VERSION "HIPBNYYYYYYYYYYYYYYYYYYYYYYYYYYYYYYYYYYYYY/4/%%%/4/'%**4YYY///"

NS_ :

BS_:

BU_: INV BMS VCU DASH DATALOGGER PDB EMeter REPRO TELEM

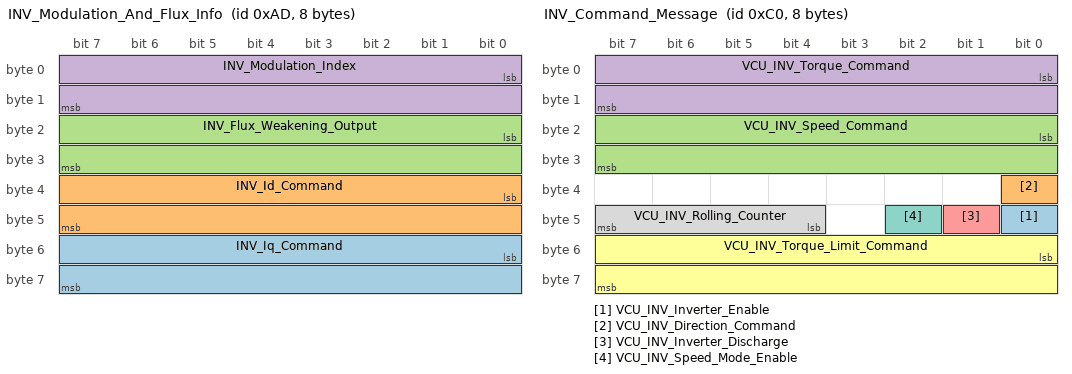
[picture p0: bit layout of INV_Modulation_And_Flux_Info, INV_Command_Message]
BO_ 173 INV_Modulation_And_Flux_Info: 8 INV
 SG_ INV_Iq_Command : 48|16@1- (0.1,0) [-3276.8|3276.7] "current:A" Vector__XXX
 SG_ INV_Id_Command : 32|16@1- (0.1,0) [-3276.8|3276.7] "current:A" Vector__XXX
 SG_ INV_Flux_Weakening_Output : 16|16@1- (0.1,0) [-3276.8|3276.7] "current:A" Vector__XXX
 SG_ INV_Modulation_Index : 0|16@1- (0.0001,0) [-3.2768|3.2767] "" Vector__XXX

BO_ 172 INV_Torque_And_Timer_Info: 8 INV
 SG_ INV_Power_On_Timer : 32|32@1+ (0.003,0) [0|12884800] "time:second" Vector__XXX
 SG_ INV_Torque_Feedback : 16|16@1- (0.1,0) [-3276.8|3276.7] "torque:N.m" Vector__XXX
 SG_ INV_Commanded_Torque : 0|16@1- (0.1,0) [-3276.8|3276.7] "torque:N.m" Vector__XXX

BO_ 194 INV_Parameter_Response: 8 INV
 SG_ INV_Parameter_Response_Write_OK : 16|1@1+ (1,0) [0|1] "" Vector__XXX
 SG_ INV_Parameter_Response_Data : 32|16@1- (1,0) [-32768|32767] "" Vector__XXX
 SG_ INV_Parameter_Response_Addr : 0|16@1+ (1,0) [0|65535] "" Vector__XXX

BO_ 193 INV_Parameter_Command: 8 VCU
 SG_ VCU_INV_Parameter_Data : 32|16@1- (1,0) [-32768|32767] "" Vector__XXX
 SG_ VCU_INV_Parameter_RW_Command : 16|1@1+ (1,0) [0|1] "" Vector__XXX
 SG_ VCU_INV_Parameter_Address : 0|16@1+ (1,0) [0|65535] "" Vector__XXX

BO_ 192 INV_Command_Message: 8 VCU
 SG_ VCU_INV_Inverter_Enable : 40|1@1+ (1,0) [0|1] "" Vector__XXX
 SG_ VCU_INV_Direction_Command : 32|1@1+ (1,0) [0|1] "" Vector__XXX
 SG_ VCU_INV_Speed_Command : 16|16@1- (1,0) [-32768|32767] "angular_speed:rpm" Vector__XXX
 SG_ VCU_INV_Torque_Command : 0|16@1- (0.1,0) [-3276.8|3276.7] "torque:N.m" Vector__XXX
 SG_ VCU_INV_Inverter_Discharge : 41|1@1+ (1,0) [0|1] "" Vector__XXX
 SG_ VCU_INV_Torque_Limit_Command : 48|16@1- (0.1,0) [-3276.8|3276.7] "torque:N.m" Vector__XXX
 SG_ VCU_INV_Speed_Mode_Enable : 42|1@1+ (1,0) [0|1] "" Vector__XXX
 SG_ VCU_INV_Rolling_Counter : 44|4@1+ (1,0) [0|15] "" Vector__XXX

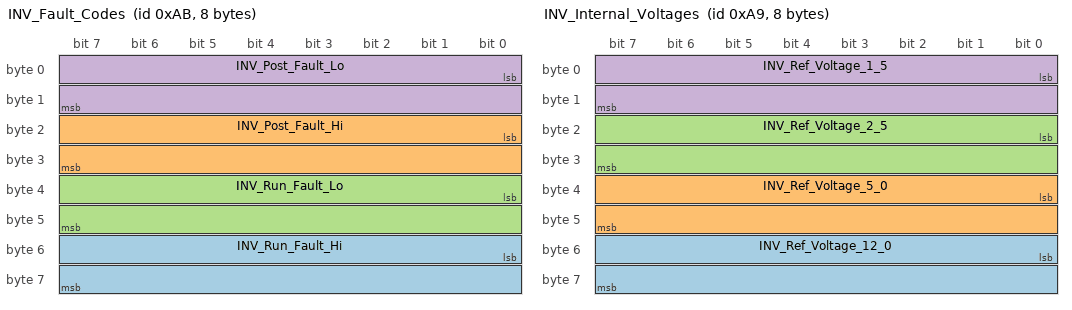
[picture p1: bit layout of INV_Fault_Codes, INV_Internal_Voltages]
BO_ 171 INV_Fault_Codes: 8 INV
 SG_ INV_Run_Fault_Hi : 48|16@1+ (1,0) [0|65535] "" Vector__XXX
 SG_ INV_Post_Fault_Hi : 16|16@1+ (1,0) [0|65535] "" Vector__XXX
 SG_ INV_Run_Fault_Lo : 32|16@1+ (1,0) [0|65535] "" Vector__XXX
 SG_ INV_Post_Fault_Lo : 0|16@1+ (1,0) [0|65535] "" Vector__XXX

BO_ 170 INV_Internal_States: 8 INV
 SG_ INV_Direction_Command : 56|1@1+ (1,0) [0|1] "" Vector__XXX
 SG_ INV_Inverter_Enable_State : 48|1@1+ (1,0) [0|1] "" Vector__XXX
 SG_ INV_Relay_3_Status : 26|1@1+ (1,0) [0|1] "" Vector__XXX
 SG_ INV_Relay_4_Status : 27|1@1+ (1,0) [0|1] "" Vector__XXX
 SG_ INV_Relay_2_Status : 25|1@1+ (1,0) [0|1] "" Vector__XXX
 SG_ INV_Inverter_Run_Mode : 32|1@1+ (1,0) [0|1] "" Vector__XXX
 SG_ INV_Inverter_Command_Mode : 40|1@1+ (1,0) [0|1] "" Vector__XXX
 SG_ INV_Relay_1_Status : 24|1@1+ (1,0) [0|1] "" Vector__XXX
 SG_ INV_Inverter_State : 16|8@1+ (1,0) [0|255] "" Vector__XXX
 SG_ INV_VSM_State : 0|8@1+ (1,0) [0|15] "" Vector__XXX
 SG_ INV_Inverter_Enable_Lockout : 55|1@1+ (1,0) [0|1] "" Vector__XXX
 SG_ INV_Inverter_Discharge_State : 37|3@1+ (1,0) [0|7] "" Vector__XXX
 SG_ INV_Relay_5_Status : 28|1@1+ (1,0) [0|1] "" Vector__XXX
 SG_ INV_Relay_6_Status : 29|1@1+ (1,0) [0|1] "" Vector__XXX
 SG_ INV_BMS_Active : 57|1@1+ (1,0) [0|1] "" Vector__XXX
 SG_ INV_BMS_Torque_Limiting : 58|1@1+ (1,0) [0|1] "" Vector__XXX
 SG_ INV_PWM_Frequency : 8|8@1+ (1,0) [0|255] "" Vector__XXX
 SG_ INV_Limit_Max_Speed : 59|1@1+ (1,0) [0|1] "" Vector__XXX
 SG_ INV_Limit_Hot_Spot : 60|1@1+ (1,0) [0|1] "" Vector__XXX
 SG_ INV_Low_Speed_Limiting : 61|1@1+ (1,0) [0|1] "" Vector__XXX
 SG_ INV_Rolling_Counter : 44|4@1+ (1,0) [0|15] "" Vector__XXX
 SG_ INV_Limit_Coolant_Derating : 62|1@1+ (1,0) [0|1] "" Vector__XXX
 SG_ INV_Self_Sensing_Assist_Enable : 33|1@1+ (1,0) [0|1] "" Vector__XXX
 SG_ INV_Limit_Stall_Burst_Model : 63|1@1+ (1,0) [0|1] "" Vector__XXX
 SG_ INV_Burst_Model_Mode : 49|1@1+ (1,0) [0|1] "" Vector__XXX
 SG_ INV_Key_Switch_Start_Status : 54|1@1+ (1,0) [0|1] "" Vector__XXX

BO_ 169 INV_Internal_Voltages: 8 INV
 SG_ INV_Ref_Voltage_12_0 : 48|16@1- (0.01,0) [-327.68|327.67] "voltage:V" Vector__XXX
 SG_ INV_Ref_Voltage_5_0 : 32|16@1- (0.01,0) [-327.68|327.67] "voltage:V" Vector__XXX
 SG_ INV_Ref_Voltage_2_5 : 16|16@1- (0.01,0) [-327.68|327.67] "voltage:V" Vector__XXX
 SG_ INV_Ref_Voltage_1_5 : 0|16@1- (0.01,0) [-327.68|327.67] "voltage:V" Vector__XXX

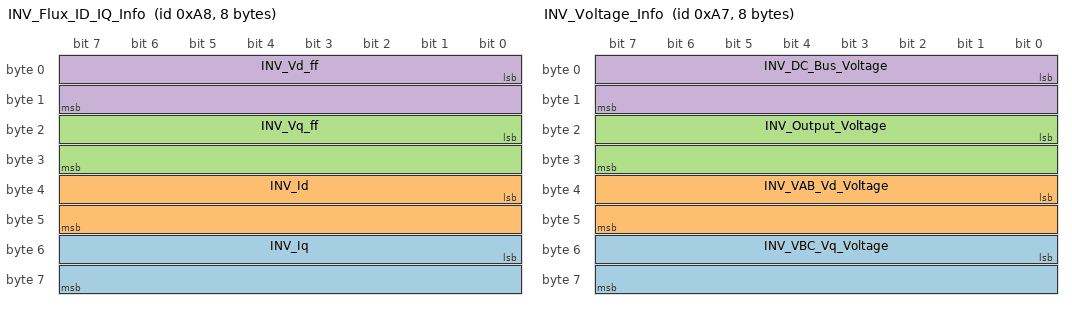
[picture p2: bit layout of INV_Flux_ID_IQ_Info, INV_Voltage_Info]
BO_ 168 INV_Flux_ID_IQ_Info: 8 INV
 SG_ INV_Iq : 48|16@1- (0.1,0) [-3276.8|3276.7] "current:A" Vector__XXX
 SG_ INV_Id : 32|16@1- (0.1,0) [-3276.8|3276.7] "current:A" Vector__XXX
 SG_ INV_Vq_ff : 16|16@1- (0.1,0) [-3276.7|3276.7] "voltage:V" Vector__XXX
 SG_ INV_Vd_ff : 0|16@1- (0.1,0) [-3276.7|3276.7] "voltage:V" Vector__XXX

BO_ 167 INV_Voltage_Info: 8 INV
 SG_ INV_VBC_Vq_Voltage : 48|16@1- (0.1,0) [-3276.8|3276.7] "voltage:V" Vector__XXX
 SG_ INV_VAB_Vd_Voltage : 32|16@1- (0.1,0) [-3276.8|3276.7] "voltage:V" Vector__XXX
 SG_ INV_Output_Voltage : 16|16@1- (0.1,0) [-3276.8|3276.7] "voltage:V" Vector__XXX
 SG_ INV_DC_Bus_Voltage : 0|16@1- (0.1,0) [-3276.8|3276.7] "voltage:V" Vector__XXX

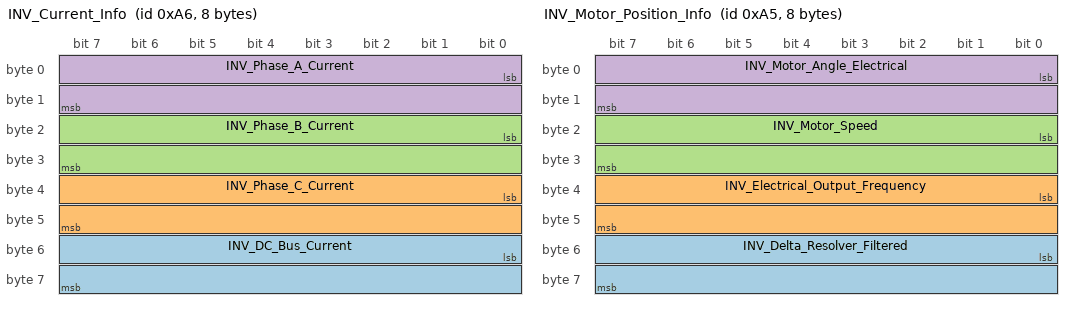
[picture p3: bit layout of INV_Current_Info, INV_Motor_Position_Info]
BO_ 166 INV_Current_Info: 8 INV
 SG_ INV_DC_Bus_Current : 48|16@1- (0.1,0) [-3276.8|3276.7] "current:A" Vector__XXX
 SG_ INV_Phase_C_Current : 32|16@1- (0.1,0) [-3276.8|3276.7] "current:A" Vector__XXX
 SG_ INV_Phase_B_Current : 16|16@1- (0.1,0) [-3276.8|3276.7] "current:A" Vector__XXX
 SG_ INV_Phase_A_Current : 0|16@1- (0.1,0) [-3276.8|3276.7] "current:A" Vector__XXX

BO_ 165 INV_Motor_Position_Info: 8 INV
 SG_ INV_Delta_Resolver_Filtered : 48|16@1- (0.1,0) [-3276.8|3276.7] "angle:deg" Vector__XXX
 SG_ INV_Electrical_Output_Frequency : 32|16@1- (0.1,0) [-3276.8|3276.7] "frequency:Hz" Vector__XXX
 SG_ INV_Motor_Speed : 16|16@1- (1,0) [-32768|32767] "angular_speed:rpm" Vector__XXX
 SG_ INV_Motor_Angle_Electrical : 0|16@1+ (0.1,0) [0|6553.5] "angle:deg" Vector__XXX

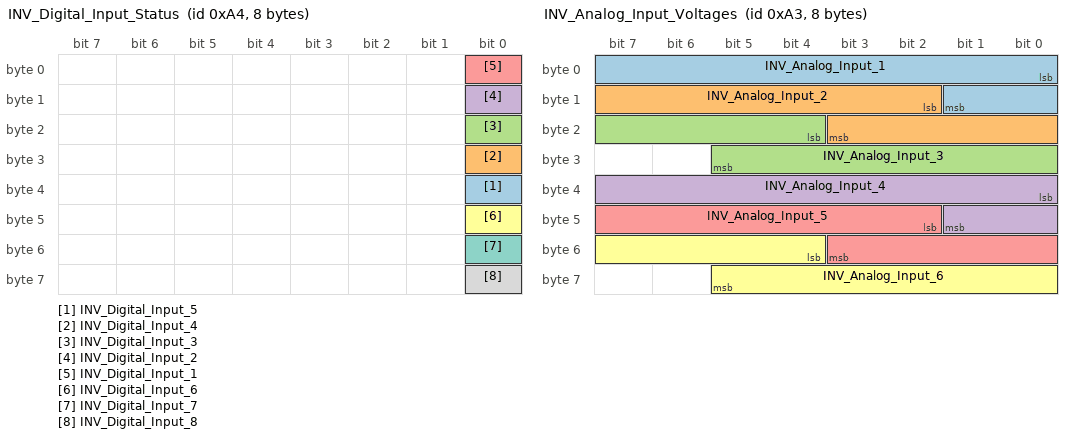
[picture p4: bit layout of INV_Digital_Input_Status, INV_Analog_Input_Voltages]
BO_ 164 INV_Digital_Input_Status: 8 INV
 SG_ INV_Digital_Input_5 : 32|1@1+ (1,0) [0|1] "" Vector__XXX
 SG_ INV_Digital_Input_4 : 24|1@1+ (1,0) [0|1] "" Vector__XXX
 SG_ INV_Digital_Input_3 : 16|1@1+ (1,0) [0|1] "" Vector__XXX
 SG_ INV_Digital_Input_2 : 8|1@1+ (1,0) [0|1] "" Vector__XXX
 SG_ INV_Digital_Input_1 : 0|1@1+ (1,0) [0|1] "" Vector__XXX
 SG_ INV_Digital_Input_6 : 40|1@1+ (1,0) [0|1] "" Vector__XXX
 SG_ INV_Digital_Input_7 : 48|1@1+ (1,0) [0|1] "" Vector__XXX
 SG_ INV_Digital_Input_8 : 56|1@1+ (1,0) [0|1] "" Vector__XXX

BO_ 163 INV_Analog_Input_Voltages: 8 INV
 SG_ INV_Analog_Input_1 : 0|10@1+ (0.01,0) [0|10.23] "voltage:V" Vector__XXX
 SG_ INV_Analog_Input_2 : 10|10@1+ (0.01,0) [0|10.23] "voltage:V" Vector__XXX
 SG_ INV_Analog_Input_3 : 20|10@1+ (0.01,0) [0|10.23] "voltage:V" Vector__XXX
 SG_ INV_Analog_Input_4 : 32|10@1+ (0.01,0) [0|10.23] "voltage:V" Vector__XXX
 SG_ INV_Analog_Input_5 : 42|10@1+ (0.01,0) [0|10.23] "voltage:V" Vector__XXX
 SG_ INV_Analog_Input_6 : 52|10@1+ (0.01,0) [0|10.23] "voltage:V" Vector__XXX

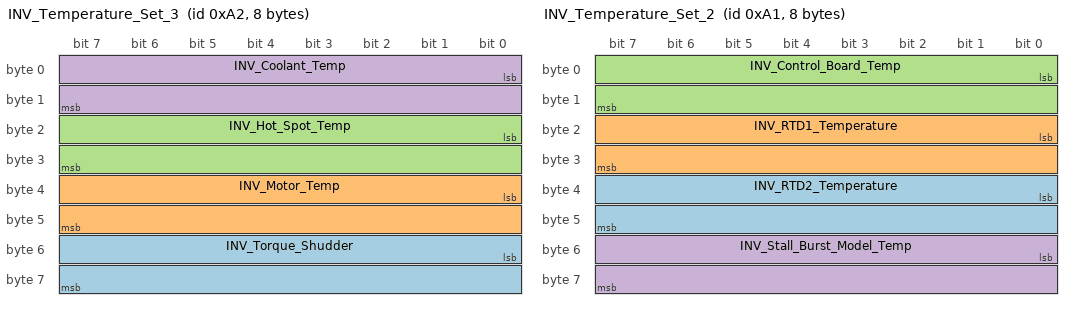
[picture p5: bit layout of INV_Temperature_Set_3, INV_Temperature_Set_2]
BO_ 162 INV_Temperature_Set_3: 8 INV
 SG_ INV_Torque_Shudder : 48|16@1- (0.1,0) [-3276.8|3276.7] "torque:N.m" Vector__XXX
 SG_ INV_Motor_Temp : 32|16@1- (0.1,0) [-3276.8|3276.7] "temperature:C" Vector__XXX
 SG_ INV_Hot_Spot_Temp : 16|16@1- (0.1,0) [-3276.8|3276.7] "temperature:C" Vector__XXX
 SG_ INV_Coolant_Temp : 0|16@1- (0.1,0) [-3276.8|3276.7] "temperature:C" Vector__XXX

BO_ 161 INV_Temperature_Set_2: 8 INV
 SG_ INV_RTD2_Temperature : 32|16@1- (0.1,0) [-3276.8|3276.7] "temperature:C" Vector__XXX
 SG_ INV_RTD1_Temperature : 16|16@1- (0.1,0) [-3276.8|3276.7] "temperature:C" Vector__XXX
 SG_ INV_Control_Board_Temp : 0|16@1- (0.1,0) [-3276.8|3276.7] "temperature:C" Vector__XXX
 SG_ INV_Stall_Burst_Model_Temp : 48|16@1- (0.1,0) [-3276.8|3276.7] "temperature:C" Vector__XXX

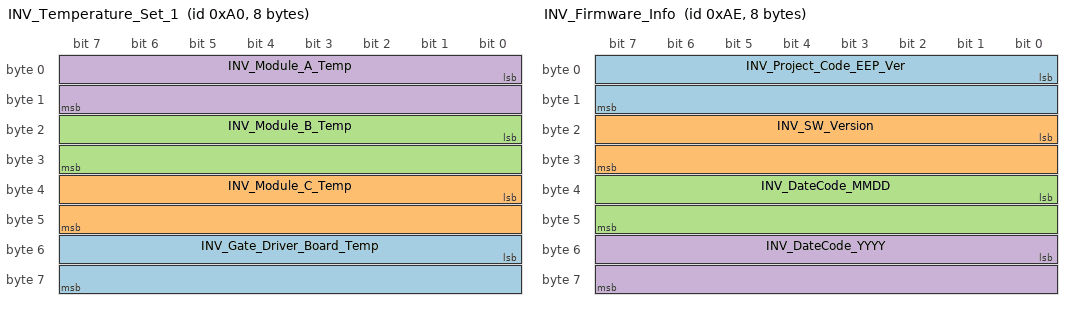
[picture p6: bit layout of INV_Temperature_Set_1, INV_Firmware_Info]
BO_ 160 INV_Temperature_Set_1: 8 INV
 SG_ INV_Gate_Driver_Board_Temp : 48|16@1- (0.1,0) [-3276.8|3276.7] "temperature:C" Vector__XXX
 SG_ INV_Module_C_Temp : 32|16@1- (0.1,0) [-3276.8|3276.7] "temperature:C" Vector__XXX
 SG_ INV_Module_B_Temp : 16|16@1- (0.1,0) [-3276.8|3276.7] "temperature:C" Vector__XXX
 SG_ INV_Module_A_Temp : 0|16@1- (0.1,0) [-3276.8|3276.7] "temperature:C" Vector__XXX

BO_ 174 INV_Firmware_Info: 8 INV
 SG_ INV_Project_Code_EEP_Ver : 0|16@1+ (1,0) [0|65535] "" Vector__XXX
 SG_ INV_SW_Version : 16|16@1+ (1,0) [0|65535] "" Vector__XXX
 SG_ INV_DateCode_MMDD : 32|16@1+ (1,0) [0|65535] "" Vector__XXX
 SG_ INV_DateCode_YYYY : 48|16@1+ (1,0) [0|65535] "" Vector__XXX

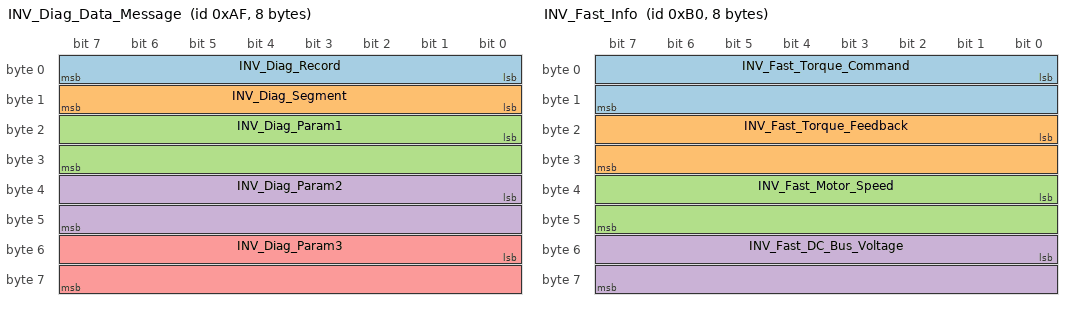
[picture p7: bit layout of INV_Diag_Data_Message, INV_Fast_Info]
BO_ 175 INV_Diag_Data_Message: 8 INV
 SG_ INV_Diag_Record : 0|8@1+ (1,0) [0|160] "" Vector__XXX
 SG_ INV_Diag_Segment M : 8|8@1+ (1,0) [0|5] "" Vector__XXX
 SG_ INV_Diag_Param1 : 16|16@1+ (1,0) [0|0] "" Vector__XXX
 SG_ INV_Diag_Param2 : 32|16@1+ (1,0) [0|0] "" Vector__XXX
 SG_ INV_Diag_Param3 : 48|16@1+ (1,0) [0|0] "" Vector__XXX

BO_ 176 INV_Fast_Info: 8 INV
 SG_ INV_Fast_Torque_Command : 0|16@1- (0.1,0) [-3276.8|32767.7] "torque:N.m" Vector__XXX
 SG_ INV_Fast_Torque_Feedback : 16|16@1- (0.1,0) [-3276.8|3276.7] "torque:N.m" Vector__XXX
 SG_ INV_Fast_Motor_Speed : 32|16@1- (1,0) [-32768|32767] "angular_speed:rpm" Vector__XXX
 SG_ INV_Fast_DC_Bus_Voltage : 48|16@1- (0.1,0) [-3276.8|3276.7] "voltage:V" Vector__XXX

BO_ 177 INV_Torque_Capability: 8 INV
 SG_ INV_Torque_Capability : 0|16@1+ (0.1,0) [0|6553.6] "torque:N.m" Vector__XXX

BO_ 244 BMS_ChargerCtrl: 8 BMS
 SG_ BMS_Max_Charging_Voltage : 7|16@0+ (0.1,0) [0|6553.5] "voltage:V" Vector__XXX
 SG_ BMS_Max_Charging_Current : 23|16@0+ (0.1,0) [0|6553.5] "current:A" Vector__XXX
 SG_ BMS_Charger_Enable : 32|1@1+ (1,0) [0|1] "" Vector__XXX

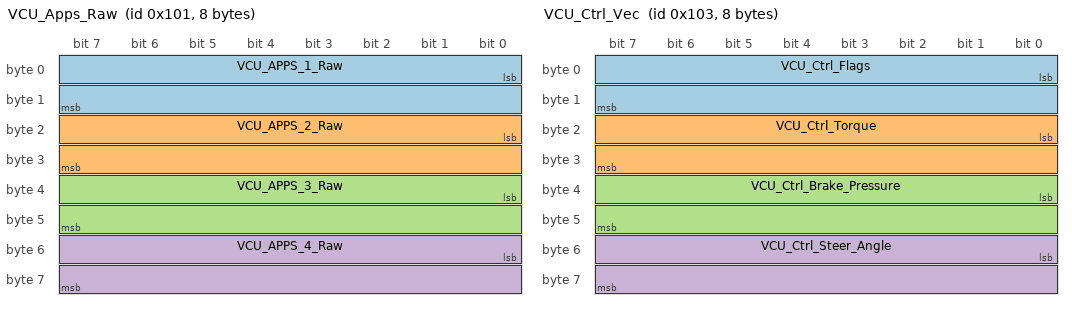
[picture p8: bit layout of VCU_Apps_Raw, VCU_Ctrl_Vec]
BO_ 257 VCU_Apps_Raw: 8 VCU
 SG_ VCU_APPS_1_Raw : 0|16@1+ (1,0) [0|4096] "" Vector__XXX
 SG_ VCU_APPS_2_Raw : 16|16@1+ (1,0) [0|4096] "" Vector__XXX
 SG_ VCU_APPS_3_Raw : 32|16@1+ (1,0) [0|4096] "" Vector__XXX
 SG_ VCU_APPS_4_Raw : 48|16@1+ (1,0) [0|4096] "" Vector__XXX

BO_ 258 VCU_BPS_Raw: 4 VCU
 SG_ VCU_FBPS_Raw : 0|16@1+ (1,0) [0|0] "" Vector__XXX
 SG_ VCU_RBPS_Raw : 16|16@1+ (1,0) [0|0] "" Vector__XXX

BO_ 259 VCU_Ctrl_Vec: 8 VCU
 SG_ VCU_Ctrl_Flags : 0|16@1- (1,0) [0|0] "" Vector__XXX
 SG_ VCU_Ctrl_Torque : 16|16@1- (0.1,0) [-220|220] "torque:N.m" Vector__XXX
 SG_ VCU_Ctrl_Brake_Pressure : 32|16@1+ (0.1,0) [0|300] "pressure:Bar" Vector__XXX
 SG_ VCU_Ctrl_Steer_Angle : 48|16@1+ (1,0) [0|0] "" Vector__XXX

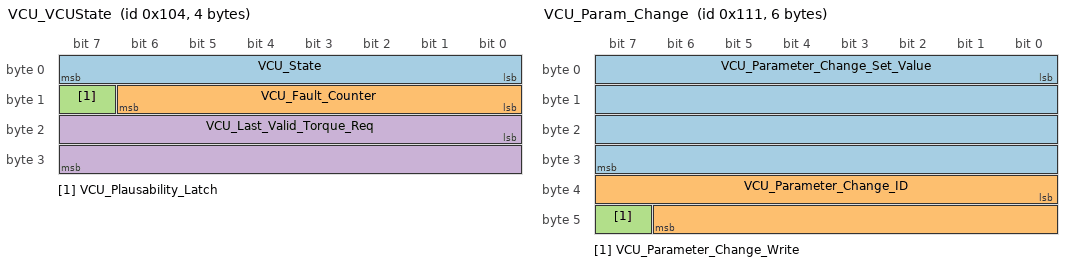
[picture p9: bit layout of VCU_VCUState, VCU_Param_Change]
BO_ 260 VCU_VCUState: 4 VCU
 SG_ VCU_State : 0|8@1+ (1,0) [0|3] "" Vector__XXX
 SG_ VCU_Fault_Counter : 8|7@1+ (1,0) [0|100] "" Vector__XXX
 SG_ VCU_Plausability_Latch : 15|1@1+ (1,0) [0|1] "" Vector__XXX
 SG_ VCU_Last_Valid_Torque_Req : 16|16@1+ (1,0) [0|0] "" Vector__XXX

BO_ 272 VCU_Param_Reveal: 6 VCU
 SG_ VCU_Parameter_Reveal_Set_Value : 0|32@1+ (1,0) [0|0] "" Vector__XXX
 SG_ VCU_Parameter_Reveal_ID : 32|16@1+ (1,0) [0|0] "" Vector__XXX

BO_ 273 VCU_Param_Change: 6 REPRO
 SG_ VCU_Parameter_Change_Set_Value : 0|32@1+ (1,0) [0|0] "" Vector__XXX
 SG_ VCU_Parameter_Change_ID : 32|15@1+ (1,0) [0|0] "" Vector__XXX
 SG_ VCU_Parameter_Change_Write : 47|1@1+ (1,0) [0|0] "" Vector__XXX

BO_ 274 VCU_Param_Request: 2 REPRO
 SG_ VCU_Parameter_Request_ID : 0|16@1+ (1,0) [0|0] "" Vector__XXX

BO_ 514 BMS_CM200_Limits: 8 BMS
 SG_ BMS_Discharge_Current_Limit : 0|16@1- (1,0) [0|0] "current:A" Vector__XXX
 SG_ BMS_Charge_Current_Limit : 16|16@1- (1,0) [0|0] "current:A" Vector__XXX

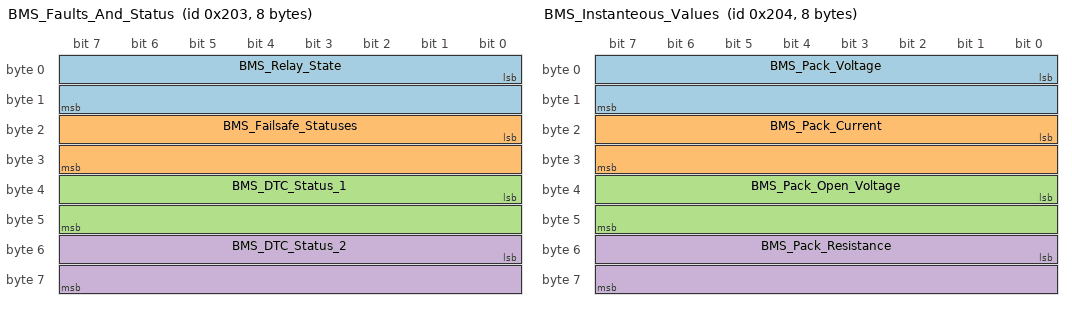
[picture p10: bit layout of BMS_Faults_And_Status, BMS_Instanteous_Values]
BO_ 515 BMS_Faults_And_Status: 8 BMS
 SG_ BMS_Relay_State : 0|16@1+ (1,0) [0|0] "" Vector__XXX
 SG_ BMS_Failsafe_Statuses : 16|16@1+ (1,0) [0|0] "" Vector__XXX
 SG_ BMS_DTC_Status_1 : 32|16@1+ (1,0) [0|0] "" Vector__XXX
 SG_ BMS_DTC_Status_2 : 48|16@1+ (1,0) [0|0] "" Vector__XXX

BO_ 516 BMS_Instanteous_Values: 8 BMS
 SG_ BMS_Pack_Voltage : 0|16@1- (0.1,0) [0|0] "voltage:V" Vector__XXX
 SG_ BMS_Pack_Current : 16|16@1- (0.1,0) [0|0] "current:A" Vector__XXX
 SG_ BMS_Pack_Open_Voltage : 32|16@1- (0.1,0) [0|0] "voltage:V" Vector__XXX
 SG_ BMS_Pack_Resistance : 48|16@1- (0.001,0) [0|0] "resistance:Ohm" Vector__XXX

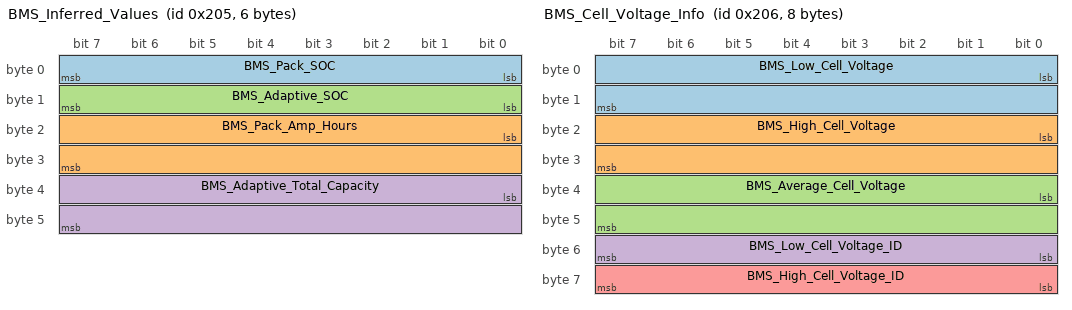
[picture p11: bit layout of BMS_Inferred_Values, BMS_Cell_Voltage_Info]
BO_ 517 BMS_Inferred_Values: 6 BMS
 SG_ BMS_Pack_SOC : 0|8@1+ (0.5,0) [0|0] "percentage:%" Vector__XXX
 SG_ BMS_Pack_Amp_Hours : 16|16@1- (0.1,0) [0|0] "capacity:Ah" Vector__XXX
 SG_ BMS_Adaptive_SOC : 8|8@1+ (0.5,0) [0|0] "percentage:%" Vector__XXX
 SG_ BMS_Adaptive_Total_Capacity : 32|16@1- (0.1,0) [0|0] "capacity:Ah" Vector__XXX

BO_ 518 BMS_Cell_Voltage_Info: 8 BMS
 SG_ BMS_Low_Cell_Voltage : 0|16@1+ (0.001,0) [0|0] "voltage:V" Vector__XXX
 SG_ BMS_High_Cell_Voltage : 16|16@1+ (0.001,0) [0|0] "voltage:V" Vector__XXX
 SG_ BMS_Average_Cell_Voltage : 32|16@1+ (0.001,0) [0|0] "voltage:V" Vector__XXX
 SG_ BMS_Low_Cell_Voltage_ID : 48|8@1+ (1,0) [0|0] "" Vector__XXX
 SG_ BMS_High_Cell_Voltage_ID : 56|8@1+ (1,0) [0|0] "" Vector__XXX

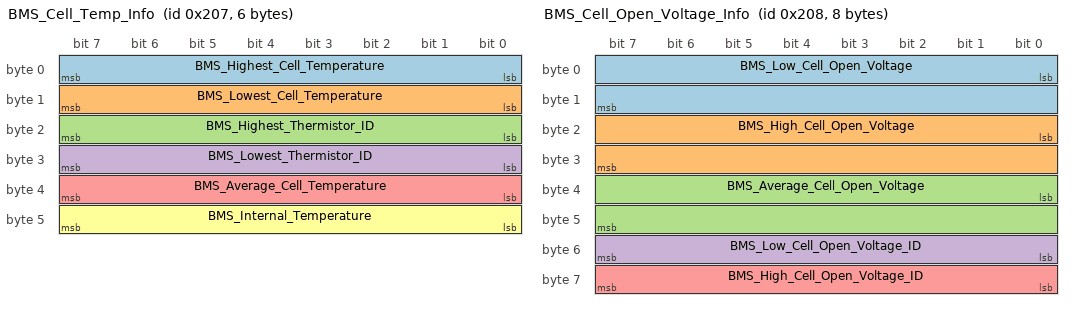
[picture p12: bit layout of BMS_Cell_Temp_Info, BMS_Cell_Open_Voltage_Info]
BO_ 519 BMS_Cell_Temp_Info: 6 BMS
 SG_ BMS_Highest_Cell_Temperature : 0|8@1- (1,0) [0|0] "temperature:C" Vector__XXX
 SG_ BMS_Lowest_Cell_Temperature : 8|8@1- (1,0) [0|0] "temperature:C" Vector__XXX
 SG_ BMS_Highest_Thermistor_ID : 16|8@1+ (1,0) [0|0] "" Vector__XXX
 SG_ BMS_Lowest_Thermistor_ID : 24|8@1+ (1,0) [0|0] "" Vector__XXX
 SG_ BMS_Average_Cell_Temperature : 32|8@1- (1,0) [0|0] "temperature:C" Vector__XXX
 SG_ BMS_Internal_Temperature : 40|8@1- (1,0) [0|0] "temperature:C" Vector__XXX

BO_ 520 BMS_Cell_Open_Voltage_Info: 8 BMS
 SG_ BMS_Low_Cell_Open_Voltage : 0|16@1+ (0.001,0) [0|0] "voltage:V" Vector__XXX
 SG_ BMS_High_Cell_Open_Voltage : 16|16@1+ (0.001,0) [0|0] "voltage:V" Vector__XXX
 SG_ BMS_Average_Cell_Open_Voltage : 32|16@1+ (0.001,0) [0|0] "voltage:V" Vector__XXX
 SG_ BMS_Low_Cell_Open_Voltage_ID : 48|8@1+ (1,0) [0|0] "" Vector__XXX
 SG_ BMS_High_Cell_Open_Voltage_ID : 56|8@1+ (1,0) [0|0] "" Vector__XXX

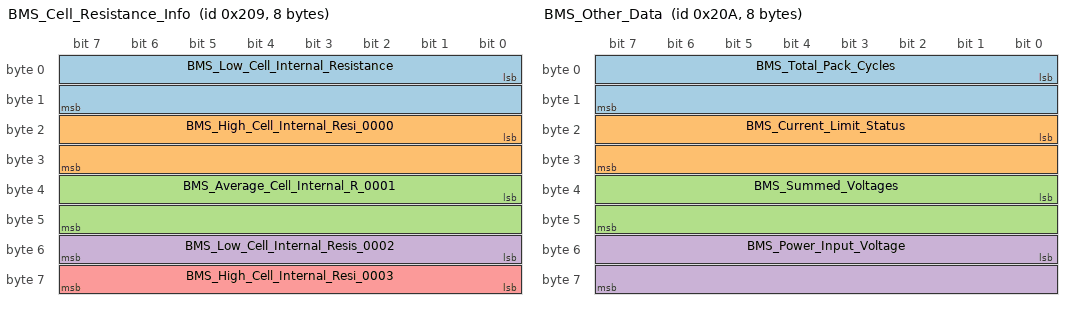
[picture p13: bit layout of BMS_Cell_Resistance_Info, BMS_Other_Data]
BO_ 521 BMS_Cell_Resistance_Info: 8 BMS
 SG_ BMS_Low_Cell_Internal_Resistance : 0|16@1- (0.01,0) [0|0] "resistance:mOhm" Vector__XXX
 SG_ BMS_High_Cell_Internal_Resi_0000 : 16|16@1- (0.01,0) [0|0] "resistance:mOhm" Vector__XXX
 SG_ BMS_Average_Cell_Internal_R_0001 : 32|16@1- (0.01,0) [0|0] "resistance:mOhm" Vector__XXX
 SG_ BMS_Low_Cell_Internal_Resis_0002 : 48|8@1+ (1,0) [0|0] "" Vector__XXX
 SG_ BMS_High_Cell_Internal_Resi_0003 : 56|8@1+ (1,0) [0|0] "" Vector__XXX

BO_ 522 BMS_Other_Data: 8 BMS
 SG_ BMS_Total_Pack_Cycles : 0|16@1+ (1,0) [0|65535] "" Vector__XXX
 SG_ BMS_Current_Limit_Status : 16|16@1+ (1,0) [0|65535] "" Vector__XXX
 SG_ BMS_Summed_Voltages : 32|16@1+ (0.01,0) [0|655.35] "voltage:V" Vector__XXX
 SG_ BMS_Power_Input_Voltage : 48|16@1+ (0.1,0) [0|6553.5] "voltage:V" Vector__XXX

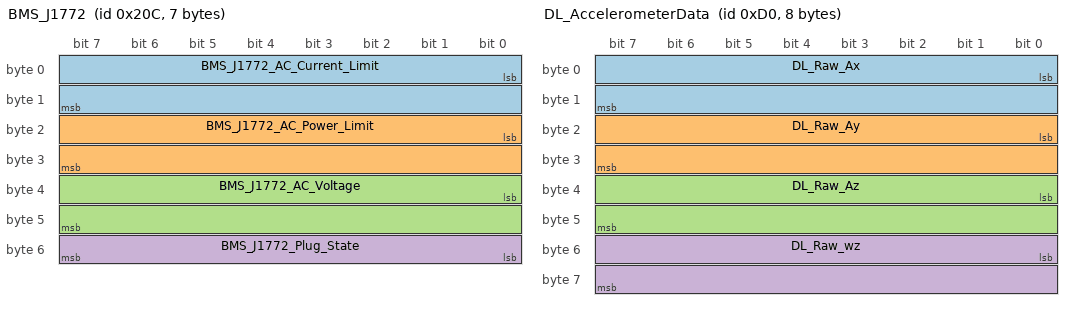
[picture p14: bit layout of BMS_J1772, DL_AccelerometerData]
BO_ 524 BMS_J1772: 7 BMS
 SG_ BMS_J1772_AC_Current_Limit : 0|16@1+ (1,0) [0|0] "" Vector__XXX
 SG_ BMS_J1772_AC_Power_Limit : 16|16@1+ (1,0) [0|0] "" Vector__XXX
 SG_ BMS_J1772_AC_Voltage : 32|16@1+ (1,0) [0|0] "" Vector__XXX
 SG_ BMS_J1772_Plug_State : 48|8@1+ (1,0) [0|0] "" Vector__XXX

BO_ 208 DL_AccelerometerData: 8 DATALOGGER
 SG_ DL_Raw_Ax : 0|16@1- (0.000244140625,0) [-7.9997558594|8] "G" Vector__XXX
 SG_ DL_Raw_Ay : 16|16@1- (0.000244140625,0) [-7.9997558594|8] "G" Vector__XXX
 SG_ DL_Raw_Az : 32|16@1- (0.000244140625,0) [-7.9997558594|8] "G" Vector__XXX
 SG_ DL_Raw_wz : 48|16@1- (0.000244140625,0) [-7.9997558594|8] "angular_speed:rad/s" Vector__XXX

BO_ 209 DL_GPSData: 8 DATALOGGER
 SG_ DL_GPS_Latitude : 0|32@1- (1.1920928955E-07,0) [0|0] "angle:deg" Vector__XXX
 SG_ DL_GPS_Longitude : 32|32@1- (1.1920928955E-07,0) [0|0] "angle:deg" Vector__XXX

BO_ 210 DL_GPSStats: 8 DATALOGGER
 SG_ DL_GPS_DOP : 32|8@1+ (1,0) [0|0] "satellites:N" Vector__XXX
 SG_ DL_GPS_Altitude : 0|32@1- (1,0) [0|0] "height:M" Vector__XXX

BO_ 211 DL_GPSUTC: 8 DATALOGGER
 SG_ DL_GPS_UTC : 0|64@1+ (0.001,0) [0|0] "time:second" Vector__XXX

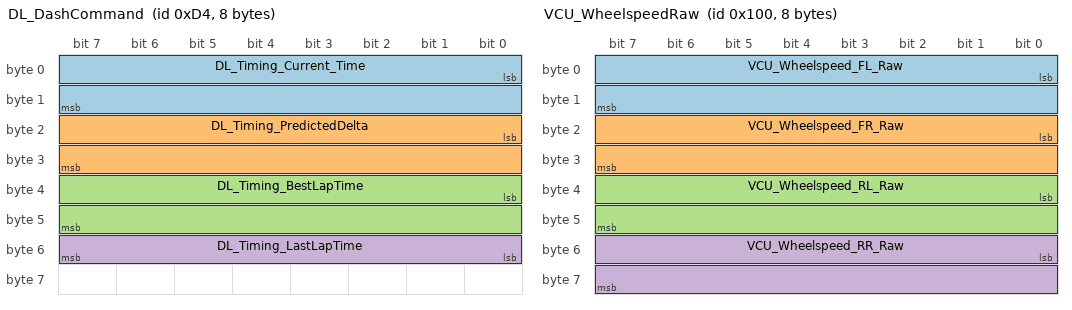
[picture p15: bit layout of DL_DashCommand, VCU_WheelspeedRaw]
BO_ 212 DL_DashCommand: 8 DATALOGGER
 SG_ DL_Timing_Current_Time : 0|16@1+ (0.01,0) [0|0] "time:second"  DASH
 SG_ DL_Timing_PredictedDelta : 16|16@1- (0.01,0) [0|0] "time:second"  DASH
 SG_ DL_Timing_BestLapTime : 32|16@1+ (0.01,0) [0|0] "time:second"  DASH
 SG_ DL_Timing_LastLapTime : 48|8@1+ (0.01,0) [0|0] "time:second"  DASH

BO_ 256 VCU_WheelspeedRaw: 8 VCU
 SG_ VCU_Wheelspeed_FL_Raw : 0|16@1- (0.001,0) [0|0] "angular_speed:rad/s" Vector__XXX
 SG_ VCU_Wheelspeed_FR_Raw : 16|16@1- (0.001,0) [0|0] "angular_speed:rad/s" Vector__XXX
 SG_ VCU_Wheelspeed_RL_Raw : 32|16@1- (0.001,0) [0|0] "angular_speed:rad/s" Vector__XXX
 SG_ VCU_Wheelspeed_RR_Raw : 48|16@1- (0.001,0) [0|0] "angular_speed:rad/s" Vector__XXX

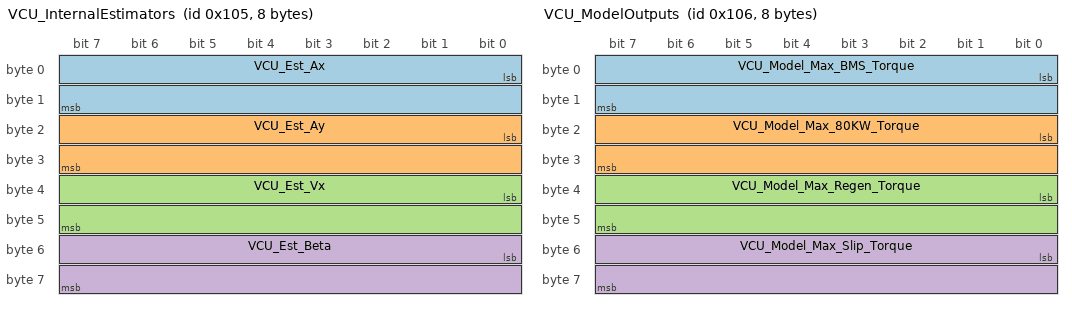
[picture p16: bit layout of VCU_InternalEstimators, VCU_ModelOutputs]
BO_ 261 VCU_InternalEstimators: 8 VCU
 SG_ VCU_Est_Ax : 0|16@1- (0.000244140625,0) [0|0] "acceleration:G" Vector__XXX
 SG_ VCU_Est_Ay : 16|16@1- (0.000244140625,0) [0|0] "acceleration:G" Vector__XXX
 SG_ VCU_Est_Vx : 32|16@1- (0.01,0) [0|0] "speed:m/s" Vector__XXX
 SG_ VCU_Est_Beta : 48|16@1- (0.01,0) [0|0] "angle:deg" Vector__XXX

BO_ 262 VCU_ModelOutputs: 8 VCU
 SG_ VCU_Model_Max_BMS_Torque : 0|16@1- (0.1,0) [0|0] "torque:N.m" Vector__XXX
 SG_ VCU_Model_Max_80KW_Torque : 16|16@1- (0.1,0) [0|0] "torque:N.m" Vector__XXX
 SG_ VCU_Model_Max_Regen_Torque : 32|16@1- (0.1,0) [0|0] "torque:N.m" Vector__XXX
 SG_ VCU_Model_Max_Slip_Torque : 48|16@1- (0.1,0) [0|0] "torque:N.m" Vector__XXX

BO_ 263 VCU_ModelState: 8 VCU
 SG_ VCU_Model_State_Placeholder : 0|64@1+ (1,0) [0|0] "" Vector__XXX

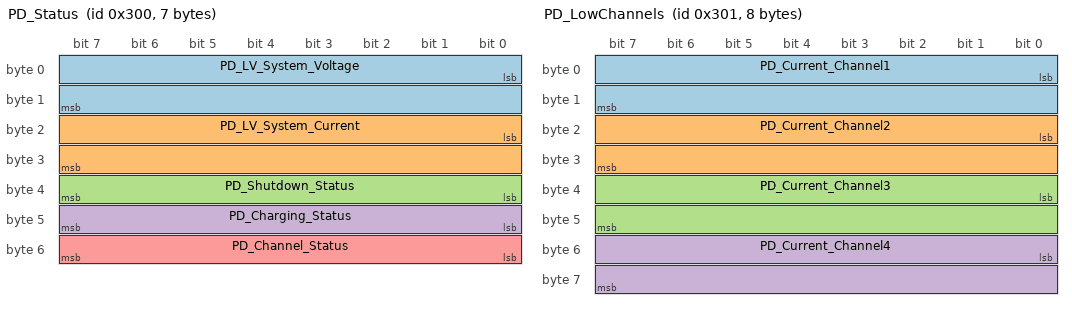
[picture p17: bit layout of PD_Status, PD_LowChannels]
BO_ 768 PD_Status: 7 PDB
 SG_ PD_LV_System_Voltage : 0|16@1- (0.1,0) [0|0] "voltage:V" Vector__XXX
 SG_ PD_LV_System_Current : 16|16@1- (0.1,0) [0|0] "current:C" Vector__XXX
 SG_ PD_Shutdown_Status : 32|8@1+ (1,0) [0|0] "" Vector__XXX
 SG_ PD_Charging_Status : 40|8@1+ (1,0) [0|0] "" Vector__XXX
 SG_ PD_Channel_Status : 48|8@1+ (1,0) [0|0] "" Vector__XXX

BO_ 769 PD_LowChannels: 8 PDB
 SG_ PD_Current_Channel1 : 0|16@1- (0.001,0) [-32.768|32.767] "Amps" Vector__XXX
 SG_ PD_Current_Channel2 : 16|16@1- (0.001,0) [-32.768|32.767] "Amps" Vector__XXX
 SG_ PD_Current_Channel3 : 32|16@1- (0.001,0) [-32.768|32.767] "Amps" Vector__XXX
 SG_ PD_Current_Channel4 : 48|16@1- (0.001,0) [-32.768|32.767] "Amps" Vector__XXX

BO_ 771 PD_ControlOrWhatever: 8 PDB
 SG_ PD_IDK : 0|64@1+ (1,0) [0|0] "" Vector__XXX

BO_ 784 PD_Param_Reveal: 6 PDB
 SG_ PDB_Parameter_Reveal_Set_Value : 0|32@1+ (1,0) [0|0] "" Vector__XXX
 SG_ PDB_Parameter_Reveal_ID : 32|16@1+ (1,0) [0|0] "" Vector__XXX

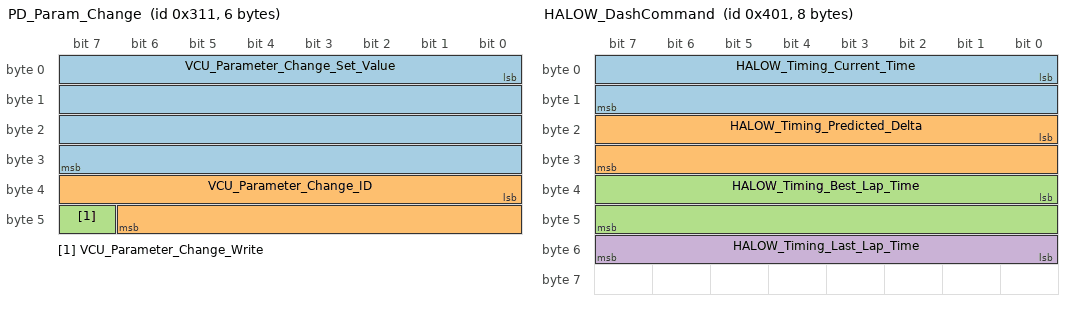
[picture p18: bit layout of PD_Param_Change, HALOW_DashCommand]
BO_ 785 PD_Param_Change: 6 REPRO
 SG_ VCU_Parameter_Change_Set_Value : 0|32@1+ (1,0) [0|0] "" Vector__XXX
 SG_ VCU_Parameter_Change_ID : 32|15@1+ (1,0) [0|0] "" Vector__XXX
 SG_ VCU_Parameter_Change_Write : 47|1@1+ (1,0) [0|0] "" Vector__XXX

BO_ 786 PD_Param_Request: 2 REPRO
 SG_ PDB_Parameter_Request_ID : 0|16@1+ (1,0) [0|0] "" Vector__XXX

BO_ 1024 HALOW_UTC: 8 TELEM
 SG_ HALOW_UTC : 0|64@1+ (1E-06,0) [0|0] "time:second" Vector__XXX

BO_ 1025 HALOW_DashCommand: 8 TELEM
 SG_ HALOW_Timing_Current_Time : 0|16@1+ (0.01,0) [0|0] "time:second"  DASH
 SG_ HALOW_Timing_Predicted_Delta : 16|16@1- (0.01,0) [0|0] "time:second"  DASH
 SG_ HALOW_Timing_Best_Lap_Time : 32|16@1+ (0.01,0) [0|0] "time:second"  DASH
 SG_ HALOW_Timing_Last_Lap_Time : 48|8@1+ (0.01,0) [0|0] "time:second"  DASH

BO_ 1040 HALOW_Param_Reveal: 6 TELEM
 SG_ HALOW_Parameter_Reveal_Set_Value : 0|32@1+ (1,0) [0|0] "" Vector__XXX
 SG_ HALOW_Parameter_Reveal_ID : 32|16@1+ (1,0) [0|0] "" Vector__XXX

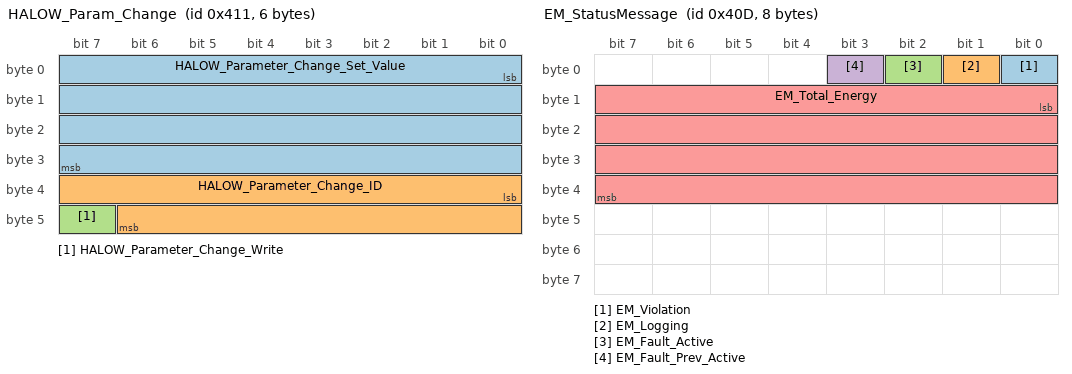
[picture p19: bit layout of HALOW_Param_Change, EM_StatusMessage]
BO_ 1041 HALOW_Param_Change: 6 REPRO
 SG_ HALOW_Parameter_Change_Set_Value : 0|32@1+ (1,0) [0|0] "" Vector__XXX
 SG_ HALOW_Parameter_Change_ID : 32|15@1+ (1,0) [0|0] "" Vector__XXX
 SG_ HALOW_Parameter_Change_Write : 47|1@1+ (1,0) [0|0] "" Vector__XXX

BO_ 1042 HALOW_Param_Request: 2 REPRO
 SG_ HALOW_Parameter_Request_ID : 0|16@1+ (1,0) [0|0] "" Vector__XXX

BO_ 770 PD_HighChannels: 8 PDB
 SG_ PD_Current_Channel5 : 0|16@1- (0.001,0) [-32768|32767] "Amps" Vector__XXX
 SG_ PD_Current_Channel6 : 16|16@1- (0.001,0) [-32768|32767] "Amps" Vector__XXX
 SG_ PD_Current_Channel7 : 32|16@1- (0.001,0) [-32768|32767] "Amps" Vector__XXX
 SG_ PD_Current_Channel8 : 48|16@1- (0.001,0) [-32768|32767] "Amps" Vector__XXX

BO_ 269 EM_MeasurementMessage: 8 EMeter
 SG_ Current : 0|32@1- (1,0) [0|0] "current:A" Vector__XXX
 SG_ Voltage : 32|32@1- (1,0) [0|0] "voltage:V" Vector__XXX

BO_ 1037 EM_StatusMessage: 8 EMeter
 SG_ EM_Violation : 0|1@1+ (1,0) [0|0] "" Vector__XXX
 SG_ EM_Logging : 1|1@1+ (1,0) [0|0] "" Vector__XXX
 SG_ EM_Fault_Active : 2|1@1+ (1,0) [0|0] "" Vector__XXX
 SG_ EM_Fault_Prev_Active : 3|1@1+ (1,0) [0|0] "" Vector__XXX
 SG_ EM_Total_Energy : 8|32@1- (1,0) [0|0] "energy:Wh" Vector__XXX

BO_ 1549 EM_TempuratureMessage: 8 BMS
 SG_ EM_Maximum_Cell_Temp : 0|16@1+ (0.1,0) [0|0] "temperature:C" Vector__XXX
 SG_ EM_Minimum_Cell_Temp : 16|16@1+ (0.1,0) [0|0] "temperature:C" Vector__XXX
 SG_ EM_Average_Cell_Temp : 32|16@1+ (0.1,0) [0|0] "temperature:C" Vector__XXX

CM_ SG_ 173 INV_Iq_Command "The commanded Q-axis current";
CM_ SG_ 173 INV_Id_Command "The commanded D-axis current";
CM_ SG_ 173 INV_Flux_Weakening_Output "This is the current output of the flux regulator.";
CM_ SG_ 173 INV_Modulation_Index "This is the modulation index. The scale factor is x100. To get the actual modulation index divide the value by 100.";
CM_ SG_ 172 INV_Power_On_Timer "Updated every 3 msec. This will roll over in approximately 150 days!";
CM_ SG_ 172 INV_Torque_Feedback "Estimated motor torque feedback";
CM_ SG_ 172 INV_Commanded_Torque "The commanded Torque";
CM_ BO_ 194 "To write a parameter use message 0x0C1 with byte #2 set to 1 (write). 
To read a parameter use message 0x0C1 with byte #2 to set 0 (read). ";
CM_ SG_ 194 INV_Parameter_Response_Write_OK "0=Write failure, 1=Success";
CM_ SG_ 194 INV_Parameter_Response_Data "Data from parameter message.  All data is 16 bits and is contained in bytes 4 and 5. Bytes 6 and 7 should be ignored.";
CM_ SG_ 194 INV_Parameter_Response_Addr "Address of parameter response message data.";
CM_ BO_ 193 "To write a parameter use message 0x0C1 with byte #2 set to 1 (write). 
To read a parameter use message 0x0C1 with byte #2 to set 0 (read). ";
CM_ SG_ 193 VCU_INV_Parameter_Data "Data to be written.  All data is 16 bits and is contained in bytes 4 and 5.";
CM_ SG_ 193 VCU_INV_Parameter_RW_Command "0=Read, 1=Write";
CM_ SG_ 193 VCU_INV_Parameter_Address "Address of parameter to be written or read.";
CM_ BO_ 192 "The command message is used to transmit data to the controller. This message is sent from a user supplied external controller to the PMxxx controller.";
CM_ SG_ 192 VCU_INV_Inverter_Enable "0=Inverter OFF, 1 = Inverter ON";
CM_ SG_ 192 VCU_INV_Direction_Command "0=Reverse, 1=Forward.  Forward is positive motor speed.";
CM_ SG_ 192 VCU_INV_Speed_Command "Speed command used when in speed mode";
CM_ SG_ 192 VCU_INV_Torque_Command "Torque command when in torque mode";
CM_ SG_ 192 VCU_INV_Inverter_Discharge "0=Discharge Disable,1=Discharge Enable";
CM_ SG_ 192 VCU_INV_Torque_Limit_Command "Torque Limit, set to 0 to keep default";
CM_ SG_ 192 VCU_INV_Speed_Mode_Enable "0 = No change to mode, 1 = change to speed mode from torque mode";
CM_ SG_ 192 VCU_INV_Rolling_Counter "Rolling Counter sent to inverter.  If used increment count with each message sent.  Otherwise can be set to 0.";
CM_ SG_ 171 INV_Run_Fault_Hi "Each bit represents a fault. Please refer to PM100 Users Manual for details.";
CM_ SG_ 171 INV_Post_Fault_Hi "Each bit represents a fault. Please refer to PM100 Users Manual for details.";
CM_ SG_ 171 INV_Run_Fault_Lo "Each bit represents a fault. Please refer to PM100 Users Manual for details.";
CM_ SG_ 171 INV_Post_Fault_Lo "Each bit represents a fault. Please refer to PM100 Users Manual for details.";
CM_ SG_ 170 INV_Direction_Command "1 = Forward
0 = 'Reverse' if inverter enabled  & 'Stopped' if inverter is disabled";
CM_ SG_ 170 INV_Inverter_Enable_State "0=Inverter Disabled, 
1=Inverter Enabled";
CM_ SG_ 170 INV_Relay_3_Status "0=OFF, 1=ON";
CM_ SG_ 170 INV_Relay_4_Status "0=OFF, 1=ON";
CM_ SG_ 170 INV_Relay_2_Status "0=OFF, 1=ON";
CM_ SG_ 170 INV_Inverter_Run_Mode "0=Torque Mode, 1=Speed Mode";
CM_ SG_ 170 INV_Inverter_Command_Mode "0=CAN mode, 1=VSM mode";
CM_ SG_ 170 INV_Relay_1_Status "0=OFF, 1=ON";
CM_ SG_ 170 INV_Inverter_State "Different states for the inverter state machine";
CM_ SG_ 170 INV_VSM_State "Different states for the vehicle state machine";
CM_ SG_ 170 INV_Inverter_Enable_Lockout "0=Lockout Disabled, 1=Lockout Enabled";
CM_ SG_ 170 INV_Inverter_Discharge_State "0 = Disabled, 1 = Enabled, 2 = Speed Check, 3 = Active, 4 = Complete, 5 = Error, 6 = Override, 7 = Timeout";
CM_ SG_ 170 INV_Relay_5_Status "0=OFF, 1=ON";
CM_ SG_ 170 INV_Relay_6_Status "0=OFF, 1=ON";
CM_ SG_ 170 INV_BMS_Active "0 = BMS Not Active, 1 = BMS Active";
CM_ SG_ 170 INV_BMS_Torque_Limiting "0 = Not Limiting, 1 = Limiting";
CM_ SG_ 170 INV_PWM_Frequency "The current active PWM frequency";
CM_ SG_ 170 INV_Limit_Max_Speed "Indicates that torque is being modified to limit the speed.";
CM_ SG_ 170 INV_Limit_Hot_Spot "Indicates that torque is being limited to limit the hot spot temp";
CM_ SG_ 170 INV_Low_Speed_Limiting "Indicates that motor current is being limited due to low motor electrical frequency.";
CM_ SG_ 170 INV_Rolling_Counter "Rolling Counter value";
CM_ SG_ 170 INV_Limit_Coolant_Derating "0 = Not limiting, 1 = Limiting";
CM_ SG_ 170 INV_Self_Sensing_Assist_Enable "1 = Self Sensing Assist Enabled, 0 = Self Sensing Assist Disabled";
CM_ SG_ 170 INV_Limit_Stall_Burst_Model "0 = Not limiting, 1 = Limiting";
CM_ SG_ 170 INV_Burst_Model_Mode "0 = Stall, 1 = High Speed";
CM_ SG_ 170 INV_Key_Switch_Start_Status "0 = OFF, 1 = ON";
CM_ SG_ 169 INV_Ref_Voltage_12_0 "12V Input Voltage";
CM_ SG_ 169 INV_Ref_Voltage_5_0 "Transducer voltage";
CM_ SG_ 169 INV_Ref_Voltage_2_5 "Internal reference voltage";
CM_ SG_ 169 INV_Ref_Voltage_1_5 "Internal reference voltage";
CM_ SG_ 168 INV_Iq "The measured Iq current";
CM_ SG_ 168 INV_Id "The measured Id current";
CM_ SG_ 168 INV_Vq_ff "The q-axis voltage feedforward";
CM_ SG_ 168 INV_Vd_ff "The d-axis voltage feedforward";
CM_ SG_ 167 INV_VBC_Vq_Voltage "Measured value of the voltage between Phase B and Phase C";
CM_ SG_ 167 INV_VAB_Vd_Voltage "Measured value of the voltage betwen phase A and Phase B";
CM_ SG_ 167 INV_Output_Voltage "The calculated value of the output voltage, in peak line-neutral volts";
CM_ SG_ 167 INV_DC_Bus_Voltage "The actual measured value of the DC bus voltage";
CM_ SG_ 166 INV_DC_Bus_Current "The Calculated DC Bus Current";
CM_ SG_ 166 INV_Phase_C_Current "The measured value of Phase C current";
CM_ SG_ 166 INV_Phase_B_Current "The measured value of Phase B current";
CM_ SG_ 166 INV_Phase_A_Current "The measured value of Phase A current";
CM_ SG_ 165 INV_Delta_Resolver_Filtered "Used in calibration of resolver angle adjustment.";
CM_ SG_ 165 INV_Electrical_Output_Frequency "The actual electrical frequency of the inverter";
CM_ SG_ 165 INV_Motor_Speed "The measured speed of the motor";
CM_ SG_ 165 INV_Motor_Angle_Electrical "The Electrical Angle of the motor as read by the encoder or resolver";
CM_ SG_ 164 INV_Digital_Input_5 "Status of Digital Input #5";
CM_ SG_ 164 INV_Digital_Input_4 "Status of Digital Input #4";
CM_ SG_ 164 INV_Digital_Input_3 "Status of Digital Input #3";
CM_ SG_ 164 INV_Digital_Input_2 "Status of Digital Input #2";
CM_ SG_ 164 INV_Digital_Input_1 "Status of Digital Input #1";
CM_ SG_ 164 INV_Digital_Input_6 "Status of Digital Input #6";
CM_ SG_ 164 INV_Digital_Input_7 "Status of Digital Input #7";
CM_ SG_ 164 INV_Digital_Input_8 "Status of Digital Input #8";
CM_ SG_ 163 INV_Analog_Input_1 "Voltage on Analog Input #1";
CM_ SG_ 163 INV_Analog_Input_2 "Voltage on Analog Input #2";
CM_ SG_ 163 INV_Analog_Input_3 "Voltage on Analog Input #3";
CM_ SG_ 163 INV_Analog_Input_4 "Voltage on Analog Input #4";
CM_ SG_ 163 INV_Analog_Input_5 "Voltage on Analog Input #5";
CM_ SG_ 163 INV_Analog_Input_6 "Voltage on Analog Input #6";
CM_ SG_ 162 INV_Torque_Shudder "Shudder compensation value of torque";
CM_ SG_ 162 INV_Motor_Temp "Motor Temperature Sensor";
CM_ SG_ 162 INV_Hot_Spot_Temp "Estimated inverter hot spot temperature";
CM_ SG_ 162 INV_Coolant_Temp "Estimated Coolant Temperature";
CM_ SG_ 161 INV_RTD2_Temperature "RTD input 2 (PT1000) Temperature";
CM_ SG_ 161 INV_RTD1_Temperature "RTD input 1 (PT1000) Temperature";
CM_ SG_ 161 INV_Control_Board_Temp "Control Board Temperature";
CM_ SG_ 161 INV_Stall_Burst_Model_Temp "Hottest temperature estimated from the stall burst thermal model feature";
CM_ SG_ 160 INV_Gate_Driver_Board_Temp "Gate Driver Board Temperature";
CM_ SG_ 160 INV_Module_C_Temp "IGBT Module C Temperature";
CM_ SG_ 160 INV_Module_B_Temp "IGBT Module B Temperature";
CM_ SG_ 160 INV_Module_A_Temp "IGBT Module A Temperature";
CM_ BO_ 176 "To enable fast message set CAN ACTIVE MSGS HI WORD to 0xFFFE.  Setting to default value of 0xFFFF will disable the fast message.";
CM_ SG_ 176 INV_Fast_Torque_Command "The commanded torque";
CM_ SG_ 176 INV_Fast_Torque_Feedback "The estimated torque";
CM_ SG_ 176 INV_Fast_Motor_Speed "Motor speed";
CM_ SG_ 176 INV_Fast_DC_Bus_Voltage "DC Bus Voltage";
CM_ SG_ 177 INV_Torque_Capability "The torque capability of the inverter given the current operating point.";
CM_ BO_ 244 "Charger_Control message";
CM_ SG_ 244 BMS_Charger_Enable "0: Start Charging
1: Stop Charging
";
CM_ BO_ 257 "Raw VCU Accelerator pedal position sensor values - before remapping
";
CM_ SG_ 257 VCU_APPS_1_Raw "Raw value as seen by the ADC";
CM_ SG_ 257 VCU_APPS_2_Raw "Raw value as seen by the ADC";
CM_ SG_ 257 VCU_APPS_3_Raw "Raw value as seen by the ADC";
CM_ SG_ 257 VCU_APPS_4_Raw "Raw value as seen by the ADC";
CM_ SG_ 258 VCU_FBPS_Raw "Raw value as seen by the ADC";
CM_ SG_ 258 VCU_RBPS_Raw "Raw value as seen by the ADC";
CM_ SG_ 259 VCU_Ctrl_Steer_Angle "We're probably removing this";
CM_ SG_ 260 VCU_State "enum: [idle, mcinit, rtd, reset]";
CM_ SG_ 260 VCU_Fault_Counter "faults until torque request is 0. torque cutoff is at 80, and counter goes to 100";
CM_ SG_ 260 VCU_Plausability_Latch "Is the APPS/BSE plausability latch in place";
CM_ SG_ 260 VCU_Last_Valid_Torque_Req "The last valid torque request that didn't generate a fault";
CM_ BO_ 208 "Stores all associated values in q3.12";
CM_ SG_ 208 DL_Raw_Ax "x acceleration in q3.12";
CM_ SG_ 208 DL_Raw_Ay "y acceleration in q3.12";
CM_ SG_ 208 DL_Raw_Az "z acceleration in q3.12";
CM_ SG_ 208 DL_Raw_wz "yaw rate in q3.12";
CM_ SG_ 209 DL_GPS_Latitude "latitude in q8.23";
CM_ SG_ 209 DL_GPS_Longitude "longitude in q8.23";
CM_ SG_ 261 VCU_Est_Vx "Estimated Vx in meters";
CM_ SG_ 261 VCU_Est_Beta "IDK yet";
BA_DEF_ BO_  "GenMsgCycleTime" INT 0 100000;
BA_DEF_  "BusType" STRING ;
BA_DEF_ BO_  "VFrameFormat" ENUM  "StandardCAN","ExtendedCAN","reserved","J1939PG","reserved","reserved","reserved","reserved","reserved","reserved","reserved","reserved","reserved","reserved","StandardCAN_FD","ExtendedCAN_FD";
BA_DEF_ BO_  "CANFD_BRS" ENUM  "0","1";
BA_DEF_  "BusId" ENUM  "reserved","Command","Data";
BA_DEF_ SG_  "SystemSignalLongSymbol" STRING ;
BA_DEF_DEF_  "GenMsgCycleTime" 0;
BA_DEF_DEF_  "BusType" "CAN";
BA_DEF_DEF_  "VFrameFormat" "StandardCAN";
BA_DEF_DEF_  "CANFD_BRS" "0";
BA_DEF_DEF_  "BusId" "Command";
BA_DEF_DEF_  "SystemSignalLongSymbol" "";
BA_ "GenMsgCycleTime" BO_ 172 10;
BA_ "GenMsgCycleTime" BO_ 192 10;
BA_ "GenMsgCycleTime" BO_ 171 100;
BA_ "GenMsgCycleTime" BO_ 170 100;
BA_ "GenMsgCycleTime" BO_ 169 100;
BA_ "GenMsgCycleTime" BO_ 168 10;
BA_ "GenMsgCycleTime" BO_ 167 10;
BA_ "GenMsgCycleTime" BO_ 166 10;
BA_ "GenMsgCycleTime" BO_ 165 10;
BA_ "GenMsgCycleTime" BO_ 164 10;
BA_ "GenMsgCycleTime" BO_ 163 10;
BA_ "GenMsgCycleTime" BO_ 162 100;
BA_ "GenMsgCycleTime" BO_ 161 100;
BA_ "GenMsgCycleTime" BO_ 160 100;
BA_ "GenMsgCycleTime" BO_ 176 3;
BA_ "GenMsgCycleTime" BO_ 177 10;
BA_ "GenMsgCycleTime" BO_ 244 500;
BA_ "GenMsgCycleTime" BO_ 257 50;
BA_ "SystemSignalLongSymbol" SG_ 521 BMS_High_Cell_Internal_Resi_0000 "BMS_High_Cell_Internal_Resistance";
BA_ "SystemSignalLongSymbol" SG_ 521 BMS_Average_Cell_Internal_R_0001 "BMS_Average_Cell_Internal_Resistance";
BA_ "SystemSignalLongSymbol" SG_ 521 BMS_Low_Cell_Internal_Resis_0002 "BMS_Low_Cell_Internal_Resistance_ID";
BA_ "SystemSignalLongSymbol" SG_ 521 BMS_High_Cell_Internal_Resi_0003 "BMS_High_Cell_Internal_Resistance_ID";
VAL_ 192 VCU_INV_Inverter_Enable 0 "Turn the inverter OFF" 1 "Turn the Inverter ON" ;
VAL_ 192 VCU_INV_Direction_Command 0 "CW" 1 "CCW" ;
VAL_ 192 VCU_INV_Inverter_Discharge 0 "Discharge Disable" 1 "Discharge Enable (if EEPROM parameter is set)" ;
VAL_ 170 INV_Inverter_State 0 "Power up" 1 "Stop" 2 "Open Loop" 3 "Closed Loop" 4 "Internal State" 5 "Internal State" 6 "Internal State" 7 "Internal State" 8 "Idle Run" 9 "Idle Stop" 10 "Internal State" 11 "Intern State" 12 "Internal State" ;
VAL_ 170 INV_VSM_State 0 "VSM Start State" 1 "Pre-Charge Init state" 2 "pre-charge active state" 3 "pre-charge complete state" 4 "VSM wait state" 5 "VSM ready state" 6 "Motor Running State" 7 "blink fault code state" 14 "Shutdown state for Key Switch Mode 1" 15 "Reset the inverter" ;
VAL_ 170 INV_Inverter_Discharge_State 0 "Disabled" 1 "Enabled" 2 "Speed Check" 3 "Active" 4 "Complete" 5 "Error" 6 "Override" 7 "Timeout" ;
VAL_ 170 INV_Limit_Stall_Burst_Model 0 "Not Limiting" 1 "Limiting" ;
VAL_ 170 INV_Burst_Model_Mode 0 "Stall" 1 "High Speed" ;
SIG_VALTYPE_ 269 Current : 1;
SIG_VALTYPE_ 269 Voltage : 1;
SIG_VALTYPE_ 1037 EM_Total_Energy : 1;
